AUTOSAR XML (schema 4-2-2)
package /Components
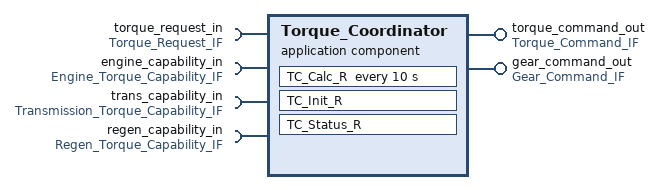
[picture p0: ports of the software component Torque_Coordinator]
  application sw component type Torque_Coordinator
    provide port torque_command_out: provided-interface=Torque_Command_IF
    provide port gear_command_out: provided-interface=Gear_Command_IF
    4 x require port:
      torque_request_in: required-interface=Torque_Request_IF
      engine_capability_in: required-interface=Engine_Torque_Capability_IF
      trans_capability_in: required-interface=Transmission_Torque_Capability_IF
      regen_capability_in: required-interface=Regen_Torque_Capability_IF
    behavior Torque_Coordinator_InternalBehavior
      data received event Capabilities_Update: start-on-event=TC_Calc_R
      init event TC_Init: start-on-event=TC_Init_R
      timing event TC_Periodic_10ms: start-on-event=TC_Calc_R, period=10
      runnable TC_Init_R: symbol=TC_Init
        parameter access PA_Init_CoordParams: accessed-parameter=torque_request_in.driver_torque_request_nm
      runnable TC_Calc_R: minimum-start-interval=10, symbol=TC_Calc
        data-receive-point-by-arguments:
          4 x access:
            VA_Arg_DriverTorqueReq: accessed-variable=torque_request_in.driver_torque_request_nm
            VA_Arg_EngineCapability: accessed-variable=engine_capability_in.engine_torque_capability_nm
            VA_Arg_TransCapability: accessed-variable=trans_capability_in.trans_torque_capability_nm
            VA_Arg_RegenCapability: accessed-variable=regen_capability_in.regen_torque_capability_nm
        data-send-points:
          4 x access:
            VA_Send_EngineTorqueCmd: accessed-variable=torque_command_out.engine_torque_cmd_nm
            VA_Send_TransTorqueCmd: accessed-variable=torque_command_out.trans_torque_cmd_nm
            VA_Send_RegenTorqueCmd: accessed-variable=torque_command_out.regen_torque_cmd_nm
            VA_Send_GearCmd: accessed-variable=gear_command_out.gear_cmd
      runnable TC_Status_R: minimum-start-interval=50, can-be-invoked-concurrently=true, symbol=TC_Status
        data-read-access:
          access VA_Read_EngineTorqueCmd: accessed-variable=torque_command_out.engine_torque_cmd_nm
